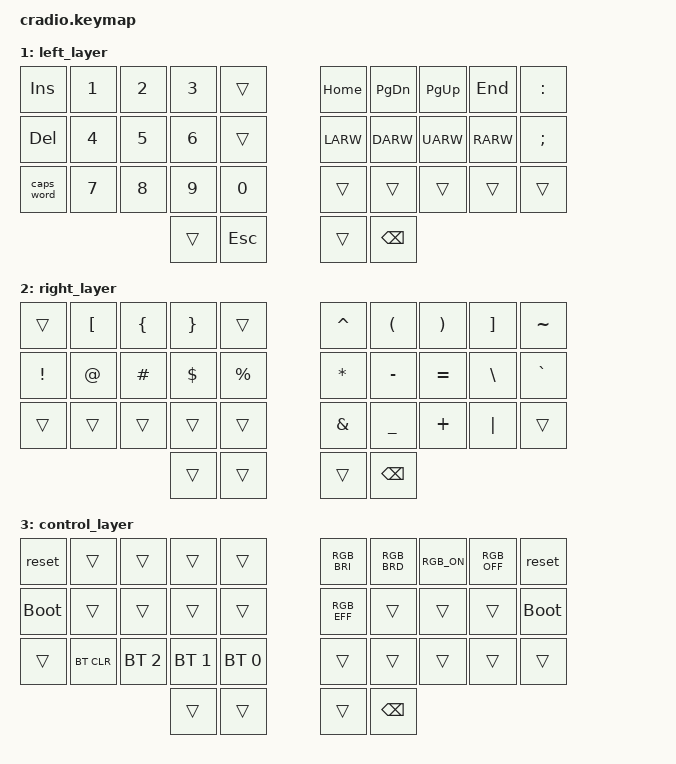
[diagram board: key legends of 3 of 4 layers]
// Copyright (c) 2022 The ZMK Contributors
// SPDX-License-Identifier: MIT

#include <behaviors.dtsi>
#include <dt-bindings/zmk/keys.h>
#include <dt-bindings/zmk/outputs.h>
#include <dt-bindings/zmk/bt.h>
#include <dt-bindings/led/led.h>
#include <dt-bindings/zmk/rgb.h>

&spi1 {
  compatible = "nordic,nrf-spim";
  status = "okay";
  mosi-pin = <33>;
  // Unused pins, needed for SPI definition, but not used by the ws2812 driver itself.
  sck-pin = <34>;
  miso-pin = <39>;

  led_strip: ws2812@0 {
    compatible = "worldsemi,ws2812-spi";
    label = "WS2812";

    /* SPI */
    reg = <0>; /* ignored, but necessary for SPI bindings */
    spi-max-frequency = <4000000>;

    /* WS2812 */
    chain-length = <10>; /* number of LEDs */
    spi-one-frame = <0x70>;
    spi-zero-frame = <0x40>;
    color-mapping = <LED_COLOR_ID_GREEN
                          LED_COLOR_ID_RED
                          LED_COLOR_ID_BLUE>;
  };
};

/ {
    chosen {
        zmk,underglow = &led_strip;
    };
};

// Home row mods macro
#define HRML(k1,k2,k3,k4) &ht LSHFT k1  &ht LALT k2  &ht LCTRL k3  &ht LGUI k4
#define HRMR(k1,k2,k3,k4) &ht RGUI k1  &ht RCTRL k2  &ht RALT k3  &ht RSHFT k4

/ {
    behaviors {
        ht: hold_tap {
            label = "hold_tap";
            compatible = "zmk,behavior-hold-tap";
            #binding-cells = <2>;
            flavor = "tap-preferred";
            tapping-term-ms = <220>;
            quick-tap-ms = <150>;
            global-quick-tap;
            bindings = <&kp>, <&kp>;
        };
    };
};  
#define COMBO(name, keypress, keypos) \
combo_##name {                        \
	timeout-ms = <100>;                \
	bindings = <keypress>;            \
	key-positions = <keypos>;         \
};

/ {
	combos {
		compatible = "zmk,combos";
		// invoke macros
		COMBO(tolayer_0,  &tolayer_0,   31  4)
		COMBO(tolayer_1,  &tolayer_1,   31  3)
		COMBO(tolayer_2,  &tolayer_2,   31  2)
		COMBO(tolayer_3,  &tolayer_3,   31  1)

	};
};

/ {	
    macros {
            ZMK_MACRO(tolayer_0,
    	    wait-ms = <0>;
    	    tap-ms = <0>;
            bindings
                = <&macro_press &to 0>
                , <&macro_tap &rgb_ug RGB_COLOR_HSB(128,100,100)>
                , <&macro_pause_for_release>
                , <&macro_release &to 0>
                , <&macro_tap &rgb_ug RGB_COLOR_HSB(210,50,50)>;
		)
		
	    ZMK_MACRO(tolayer_1,
	    wait-ms = <0>;
    	    tap-ms = <0>;
            bindings
                = <&macro_press &to 1>
                , <&macro_tap &rgb_ug RGB_COLOR_HSB(128,100,100)>
                , <&macro_pause_for_release>
                , <&macro_release &to 1>
                , <&macro_tap &rgb_ug RGB_COLOR_HSB(353,50,45)>;
		)
		
	    ZMK_MACRO(tolayer_2,
	    wait-ms = <0>;
    	    tap-ms = <0>;
            bindings
                = <&macro_press &to 2>
                , <&macro_tap &rgb_ug RGB_COLOR_HSB(128,100,100)>
                , <&macro_pause_for_release>
                , <&macro_release &to 2>
                , <&macro_tap &rgb_ug RGB_COLOR_HSB(54,92,45)>;
		)
		
	    ZMK_MACRO(tolayer_3,
	    wait-ms = <0>;
    	    tap-ms = <0>;
            bindings 
		= <&macro_press &to 3>
                , <&macro_tap &rgb_ug RGB_COLOR_HSB(128,100,100)>
                , <&macro_pause_for_release>
                , <&macro_release &to 3>
                , <&macro_tap &rgb_ug RGB_COLOR_HSB(225,100,100)>;
		)
    };
};

&caps_word {
    continue-list = <UNDERSCORE MINUS>;
};

/ {
    keymap {
        compatible = "zmk,keymap";
        default_layer {
            bindings = <
        //╭──────────┬──────────┬──────────┬──────────┬──────────╮   ╭──────────┬──────────┬──────────┬──────────┬──────────╮
        //│  Q       │  W       │  E       │  R       │  T       │   │  Y       │  U       │  I       │  O       │  P       │
            &kp Q      &kp W      &kp E      &kp R      &kp T          &kp Y      &kp U      &kp I      &kp O      &kp P
        //├──────────┼──────────┼──────────┼──────────┼──────────┤   ├──────────┼──────────┼──────────┼──────────┼──────────┤
        //│  A       │  S       │  D       │  F       │  G       │   │  H       │  J       │  K       │  L       │ ' "      │
            HRML(A,        S,         D,         F)     &kp G          &kp H      HRMR(J,        K,         L,        SQT)
        //├──────────┼──────────┼──────────┼──────────┼──────────┤   ├──────────┼──────────┼──────────┼──────────┼──────────┤
        //│  Z       │  X       │  C       │  V       │  B       │   │  N       │  M       │ , <      │ . >      │ / ?      │
            &kp Z      &kp X      &kp C      &kp V      &kp B          &kp N      &kp M      &kp COMMA  &kp DOT    &kp FSLH
        //╰──────────┴──────────┴──────────┼──────────┼──────────┤   ├──────────┼──────────┼──────────┴──────────┴──────────╯
                                             &kp TAB    &kp ENTER      &kp SPACE  &kp BSPC
        //                                 ╰──────────┴──────────╯   ╰──────────┴──────────╯
            >;
        };

        left_layer {
            bindings = <
        //╭──────────┬──────────┬──────────┬──────────┬──────────╮   ╭──────────┬──────────┬──────────┬──────────┬──────────╮
        //│ INSERT   │  1       │  2       │  3       │          │   │ HOME     │ PAGE DN  │ PAGE UP  │ END      │  :       │
            &kp INS    &kp N1     &kp N2     &kp N3     &trans         &kp HOME   &kp PG_DN  &kp PG_UP  &kp END    &kp COLON
        //├──────────┼──────────┼──────────┼──────────┼──────────┤   ├──────────┼──────────┼──────────┼──────────┼──────────┤
        //│ DELETE   │  4       │  5       │  6       │          │   │ LEFT     │ DOWN     │ UP       │ RIGHT    │  ;       │
            &kp DEL    &kp N4     &kp N5     &kp N6     &trans         &kp LARW   &kp DARW   &kp UARW   &kp RARW   &kp SEMI
        //├──────────┼──────────┼──────────┼──────────┼──────────┤   ├──────────┼──────────┼──────────┼──────────┼──────────┤
        //│ CAPS     │  7       │  8       │  9       │  0       │   │          │          │          │          │          │
           &caps_word  &kp N7     &kp N8     &kp N9     &kp N0         &trans     &trans     &trans     &trans     &trans
        //╰──────────┴──────────┴──────────┼──────────┼──────────┤   ├──────────┼──────────┼──────────┴──────────┴──────────╯
                                             &trans     &kp ESC        &trans     &kp BSPC
        //                                 ╰──────────┴──────────╯   ╰──────────┴──────────╯
            >;
        };

        right_layer {
            bindings = <
        //╭──────────┬──────────┬──────────┬──────────┬──────────╮   ╭──────────┬──────────┬──────────┬──────────┬──────────╮
        //│          │  [       │  {       │  }       │          │   │  ^       │  (       │  )       │  ]       │  ~       │
            &trans     &kp LBKT   &kp LBRC   &kp RBRC   &trans         &kp CARET  &kp LPAR   &kp RPAR   &kp RBKT   &kp TILDE
        //├──────────┼──────────┼──────────┼──────────┼──────────┤   ├──────────┼──────────┼──────────┼──────────┼──────────┤
        //│  !       │  @       │  #       │  $       │  %       │   │  *       │  -       │  =       │  \       │  `       │
            &kp EXCL   &kp AT     &kp HASH   &kp DLLR   &kp PRCNT      &kp ASTRK  &kp MINUS  &kp EQUAL  &kp BSLH   &kp GRAVE
        //├──────────┼──────────┼──────────┼──────────┼──────────┤   ├──────────┼──────────┼──────────┼──────────┼──────────┤
        //│          │          │          │          │          │   │  &       │  _       │  +       │  │       │          │
            &trans     &trans     &trans     &trans     &trans         &kp AMPS   &kp UNDER  &kp PLUS   &kp PIPE   &trans
        //╰──────────┴──────────┴──────────┼──────────┼──────────┤   ├──────────┼──────────┼──────────┴──────────┴──────────╯
                                             &trans     &trans         &trans     &kp BSPC
        //                                 ╰──────────┴──────────╯   ╰──────────┴──────────╯
            >;
        };

        control_layer {
            bindings = <
        //╭──────────┬──────────┬──────────┬──────────┬──────────╮   ╭──────────┬──────────┬──────────┬──────────┬──────────╮
        //│ RESET    │          │          │          │          │   │   LED +  │  LED -   │  LED ON  │ LED OFF  │  RESET   │
            &reset     &trans     &trans     &trans     &trans       &kp RGB_BRI &kp RGB_BRD &kp RGB_ON &kp RGB_OFF &reset
        //├──────────┼──────────┼──────────┼──────────┼──────────┤   ├──────────┼──────────┼──────────┼──────────┼──────────┤
        //│BOOTLOADER│          │          │          │          │   │ LED EFF  │          │          │          │BOOTLOADER│
          &bootloader  &trans     &trans     &trans     &trans       &kp RGB_EFF   &trans     &trans     &trans     &bootloader
        //├──────────┼──────────┼──────────┼──────────┼──────────┤   ├──────────┼──────────┼──────────┼──────────┼──────────┤
        //│          │ CLEAR BT │ PROFILE 2│ PROFILE 1│ PROFILE 0|   |          │          │          │          │          │
            &trans   &bt BT_CLR &bt BT_SEL 2 &bt BT_SEL 1 &bt BT_SEL 0 &trans     &trans     &trans     &trans      &trans   
        //╰──────────┴──────────┴──────────┼──────────┼──────────┤   ├──────────┼──────────┼──────────┴──────────┴──────────╯
                                             &trans     &trans         &trans    &kp BSPC
        //                                 ╰──────────┴──────────╯   ╰──────────┴──────────╯
            >;
        };
    };
};
